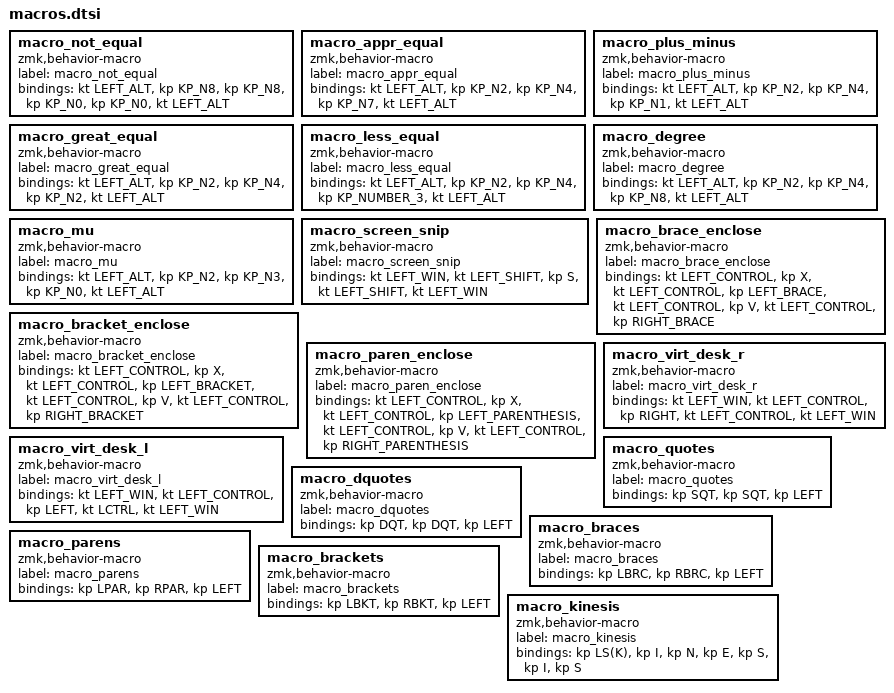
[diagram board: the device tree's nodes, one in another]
macro_not_equal: macro_not_equal{
compatible = "zmk,behavior-macro";
label = "macro_not_equal";
#binding-cells = <0>;
bindings = <&kt LEFT_ALT>, <&kp KP_N8>, <&kp KP_N8>, <&kp KP_N0>, <&kp KP_N0>, <&kt LEFT_ALT>;
};
macro_appr_equal: macro_appr_equal{
compatible = "zmk,behavior-macro";
label = "macro_appr_equal";
#binding-cells = <0>;
bindings = <&kt LEFT_ALT>, <&kp KP_N2>, <&kp KP_N4>, <&kp KP_N7>, <&kt LEFT_ALT>;
};
macro_plus_minus: macro_plus_minus{
compatible = "zmk,behavior-macro";
label = "macro_plus_minus";
#binding-cells = <0>;
bindings = <&kt LEFT_ALT>, <&kp KP_N2>, <&kp KP_N4>, <&kp KP_N1>, <&kt LEFT_ALT>;
};
macro_great_equal: macro_great_equal{
compatible = "zmk,behavior-macro";
label = "macro_great_equal";
#binding-cells = <0>;
bindings = <&kt LEFT_ALT>, <&kp KP_N2>, <&kp KP_N4>, <&kp KP_N2>, <&kt LEFT_ALT>;
};
macro_less_equal: macro_less_equal{
compatible = "zmk,behavior-macro";
label = "macro_less_equal";
#binding-cells = <0>;
bindings = <&kt LEFT_ALT>, <&kp KP_N2>, <&kp KP_N4>, <&kp KP_NUMBER_3>, <&kt LEFT_ALT>;
};
macro_degree: macro_degree{
compatible = "zmk,behavior-macro";
label = "macro_degree";
#binding-cells = <0>;
bindings = <&kt LEFT_ALT>, <&kp KP_N2>, <&kp KP_N4>, <&kp KP_N8>, <&kt LEFT_ALT>;
};
macro_mu: macro_mu{
compatible = "zmk,behavior-macro";
label = "macro_mu";
#binding-cells = <0>;
bindings = <&kt LEFT_ALT>, <&kp KP_N2>, <&kp KP_N3>, <&kp KP_N0>, <&kt LEFT_ALT>;
};
macro_screen_snip: macro_screen_snip{
compatible = "zmk,behavior-macro";
label = "macro_screen_snip";
#binding-cells = <0>;
bindings = <&kt LEFT_WIN>, <&kt LEFT_SHIFT>, <&kp S>, <&kt LEFT_SHIFT>, <&kt LEFT_WIN>;
};
macro_brace_enclose: macro_brace_enclose{
compatible = "zmk,behavior-macro";
label = "macro_brace_enclose";
#binding-cells = <0>;
bindings = <&kt LEFT_CONTROL>, <&kp X>, <&kt LEFT_CONTROL>, <&kp LEFT_BRACE>, <&kt LEFT_CONTROL>, <&kp V>, <&kt LEFT_CONTROL>, <&kp RIGHT_BRACE>;
};
macro_bracket_enclose: macro_bracket_enclose{
compatible = "zmk,behavior-macro";
label = "macro_bracket_enclose";
#binding-cells = <0>;
bindings = <&kt LEFT_CONTROL>, <&kp X>, <&kt LEFT_CONTROL>, <&kp LEFT_BRACKET>, <&kt LEFT_CONTROL>, <&kp V>, <&kt LEFT_CONTROL>, <&kp RIGHT_BRACKET>;
};
macro_paren_enclose: macro_paren_enclose{
compatible = "zmk,behavior-macro";
label = "macro_paren_enclose";
#binding-cells = <0>;
bindings = <&kt LEFT_CONTROL>, <&kp X>, <&kt LEFT_CONTROL>, <&kp LEFT_PARENTHESIS>, <&kt LEFT_CONTROL>, <&kp V>, <&kt LEFT_CONTROL>, <&kp RIGHT_PARENTHESIS>;
};
macro_virt_desk_r: macro_virt_desk_r{
compatible = "zmk,behavior-macro";
label = "macro_virt_desk_r";
#binding-cells = <0>;
bindings = <&kt LEFT_WIN>, <&kt LEFT_CONTROL>, <&kp RIGHT>, <&kt LEFT_CONTROL>, <&kt LEFT_WIN>;
};
macro_virt_desk_l: macro_virt_desk_l{
compatible = "zmk,behavior-macro";
label = "macro_virt_desk_l";
#binding-cells = <0>;
bindings = <&kt LEFT_WIN>, <&kt LEFT_CONTROL>, <&kp LEFT>, <&kt LCTRL>, <&kt LEFT_WIN>;
};
macro_quotes: macro_quotes{
compatible = "zmk,behavior-macro";
label = "macro_quotes";
#binding-cells = <0>;
bindings = <&kp SQT>, <&kp SQT>, <&kp LEFT>;
};
macro_dquotes: macro_dquotes{
compatible = "zmk,behavior-macro";
label = "macro_dquotes";
#binding-cells = <0>;
bindings = <&kp DQT>, <&kp DQT>, <&kp LEFT>;
};
macro_braces: macro_braces{
compatible = "zmk,behavior-macro";
label = "macro_braces";
#binding-cells = <0>;
bindings = <&kp LBRC>, <&kp RBRC>, <&kp LEFT>;
};
macro_parens: macro_parens{
compatible = "zmk,behavior-macro";
label = "macro_parens";
#binding-cells = <0>;
bindings = <&kp LPAR>, <&kp RPAR>, <&kp LEFT>;
};
macro_brackets: macro_brackets{
compatible = "zmk,behavior-macro";
label = "macro_brackets";
#binding-cells = <0>;
bindings = <&kp LBKT>, <&kp RBKT>, <&kp LEFT>;
};
macro_kinesis: macro_kinesis{
compatible = "zmk,behavior-macro";
label = "macro_kinesis";
#binding-cells = <0>;
bindings = <&kp LS(K)>, <&kp I>, <&kp N>, <&kp E>, <&kp S>, <&kp I>, <&kp S>;
};
